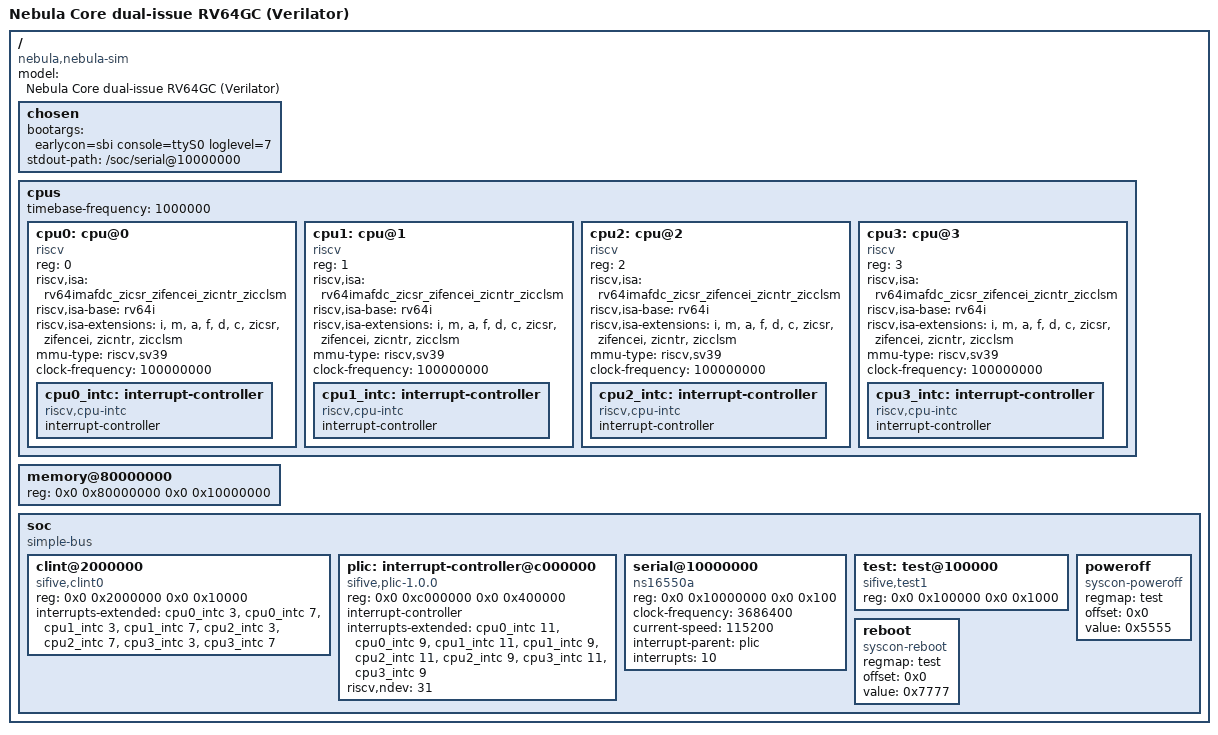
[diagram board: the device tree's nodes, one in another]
/*
 * nebula_sim.dts — SoC simulado do Nebula Core (tb/sim/nebula_sim.cpp)
 * 4 harts RV64IMAFDC Sv39, 256 MB RAM, CLINT, PLIC, UART 16550A, finisher.
 */
/dts-v1/;

/ {
	#address-cells = <2>;
	#size-cells = <2>;
	compatible = "nebula,nebula-sim";
	model = "Nebula Core dual-issue RV64GC (Verilator)";

	chosen {
		bootargs = "earlycon=sbi console=ttyS0 loglevel=7";
		stdout-path = "/soc/serial@10000000";
	};

	cpus {
		#address-cells = <1>;
		#size-cells = <0>;
		timebase-frequency = <1000000>;

		cpu0: cpu@0 {
			device_type = "cpu";
			reg = <0>;
			status = "okay";
			compatible = "riscv";
			riscv,isa = "rv64imafdc_zicsr_zifencei_zicntr_zicclsm";
			riscv,isa-base = "rv64i";
			riscv,isa-extensions = "i", "m", "a", "f", "d", "c", "zicsr", "zifencei", "zicntr", "zicclsm";
			mmu-type = "riscv,sv39";
			clock-frequency = <100000000>;

			cpu0_intc: interrupt-controller {
				#interrupt-cells = <1>;
				interrupt-controller;
				compatible = "riscv,cpu-intc";
			};
		};
		cpu1: cpu@1 {
			device_type = "cpu";
			reg = <1>;
			status = "okay";
			compatible = "riscv";
			riscv,isa = "rv64imafdc_zicsr_zifencei_zicntr_zicclsm";
			riscv,isa-base = "rv64i";
			riscv,isa-extensions = "i", "m", "a", "f", "d", "c", "zicsr", "zifencei", "zicntr", "zicclsm";
			mmu-type = "riscv,sv39";
			clock-frequency = <100000000>;

			cpu1_intc: interrupt-controller {
				#interrupt-cells = <1>;
				interrupt-controller;
				compatible = "riscv,cpu-intc";
			};
		};
		cpu2: cpu@2 {
			device_type = "cpu";
			reg = <2>;
			status = "okay";
			compatible = "riscv";
			riscv,isa = "rv64imafdc_zicsr_zifencei_zicntr_zicclsm";
			riscv,isa-base = "rv64i";
			riscv,isa-extensions = "i", "m", "a", "f", "d", "c", "zicsr", "zifencei", "zicntr", "zicclsm";
			mmu-type = "riscv,sv39";
			clock-frequency = <100000000>;

			cpu2_intc: interrupt-controller {
				#interrupt-cells = <1>;
				interrupt-controller;
				compatible = "riscv,cpu-intc";
			};
		};
		cpu3: cpu@3 {
			device_type = "cpu";
			reg = <3>;
			status = "okay";
			compatible = "riscv";
			riscv,isa = "rv64imafdc_zicsr_zifencei_zicntr_zicclsm";
			riscv,isa-base = "rv64i";
			riscv,isa-extensions = "i", "m", "a", "f", "d", "c", "zicsr", "zifencei", "zicntr", "zicclsm";
			mmu-type = "riscv,sv39";
			clock-frequency = <100000000>;

			cpu3_intc: interrupt-controller {
				#interrupt-cells = <1>;
				interrupt-controller;
				compatible = "riscv,cpu-intc";
			};
		};
	};

	memory@80000000 {
		device_type = "memory";
		reg = <0x0 0x80000000 0x0 0x10000000>;
	};

	soc {
		#address-cells = <2>;
		#size-cells = <2>;
		compatible = "simple-bus";
		ranges;

		clint@2000000 {
			compatible = "sifive,clint0", "riscv,clint0";
			reg = <0x0 0x2000000 0x0 0x10000>;
			interrupts-extended = <&cpu0_intc 3>, <&cpu0_intc 7>, <&cpu1_intc 3>, <&cpu1_intc 7>, <&cpu2_intc 3>, <&cpu2_intc 7>, <&cpu3_intc 3>, <&cpu3_intc 7>;
		};

		plic: interrupt-controller@c000000 {
			compatible = "sifive,plic-1.0.0", "riscv,plic0";
			reg = <0x0 0xc000000 0x0 0x400000>;
			#address-cells = <0>;
			#interrupt-cells = <1>;
			interrupt-controller;
			interrupts-extended = <&cpu0_intc 11>, <&cpu0_intc 9>, <&cpu1_intc 11>, <&cpu1_intc 9>, <&cpu2_intc 11>, <&cpu2_intc 9>, <&cpu3_intc 11>, <&cpu3_intc 9>;
			riscv,ndev = <31>;
		};

		serial@10000000 {
			compatible = "ns16550a";
			reg = <0x0 0x10000000 0x0 0x100>;
			clock-frequency = <3686400>;
			current-speed = <115200>;
			interrupt-parent = <&plic>;
			interrupts = <10>;
		};

		test: test@100000 {
			compatible = "sifive,test1", "sifive,test0", "syscon";
			reg = <0x0 0x100000 0x0 0x1000>;
		};

		poweroff {
			compatible = "syscon-poweroff";
			regmap = <&test>;
			offset = <0x0>;
			value = <0x5555>;
		};

		reboot {
			compatible = "syscon-reboot";
			regmap = <&test>;
			offset = <0x0>;
			value = <0x7777>;
		};
	};
};
